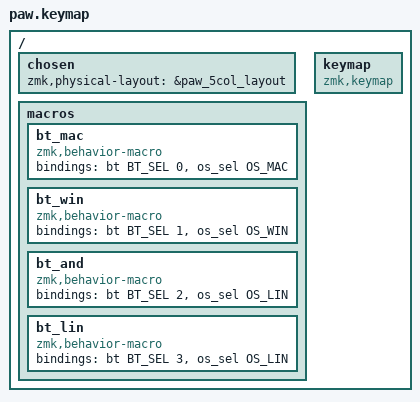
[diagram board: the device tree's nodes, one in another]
#include <behaviors.dtsi>
#include <dt-bindings/zmk/keys.h>
#include <dt-bindings/zmk/bt.h>
#include <dt-bindings/zmk/oskey.h>
#include <behaviors/oskey.dtsi>

#define BASE    0
#define MIRROR  1
#define SYM     2
#define BRAC    3
#define NAV     4
#define FUNC    5
#define NUM     6
#define WIN     7
#define MEDIA   8
#define BT      9
#define SWITCH  10
#define CMD     11
#define APP     12

#include "behaviors.dtsi"
#include "combos.dtsi"
/ {
    chosen {
        zmk,physical-layout = &paw_5col_layout;
    };

    macros {
        bt_mac: bt_mac {
            compatible = "zmk,behavior-macro";
            #binding-cells = <0>;
            bindings = <&bt BT_SEL 0>, <&os_sel OS_MAC>;
        };

        bt_win: bt_win {
            compatible = "zmk,behavior-macro";
            #binding-cells = <0>;
            bindings = <&bt BT_SEL 1>, <&os_sel OS_WIN>;
        };

        bt_and: bt_and {
            compatible = "zmk,behavior-macro";
            #binding-cells = <0>;
            bindings = <&bt BT_SEL 2>, <&os_sel OS_LIN>;
        };

        bt_lin: bt_lin {
            compatible = "zmk,behavior-macro";
            #binding-cells = <0>;
            bindings = <&bt BT_SEL 3>, <&os_sel OS_LIN>;
        };
    };

    keymap {
        compatible = "zmk,keymap";

        #include "layers/base.dtsi"
        #include "layers/mirror.dtsi"
        #include "layers/symbol.dtsi"
        #include "layers/bracket.dtsi"
        #include "layers/nav.dtsi"
        #include "layers/function.dtsi"
        #include "layers/number.dtsi"
        #include "layers/window.dtsi"
        #include "layers/media.dtsi"
        #include "layers/bluetooth.dtsi"
        #include "layers/switch.dtsi"
        #include "layers/command.dtsi"
        #include "layers/app.dtsi"
    };
};
